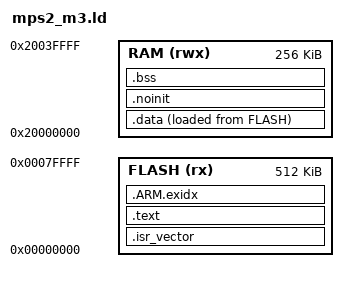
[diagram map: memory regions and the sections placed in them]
/* Linker script for QEMU "mps2-an385" (Cortex-M3): code at 0x00000000, RAM at 0x20000000. */
ENTRY(Reset_Handler)

MEMORY
{
    FLASH (rx)  : ORIGIN = 0x00000000, LENGTH = 512K
    RAM   (rwx) : ORIGIN = 0x20000000, LENGTH = 256K
}

_estack = ORIGIN(RAM) + LENGTH(RAM);

SECTIONS
{
    .isr_vector : { KEEP(*(.isr_vector)) } > FLASH
    .text : { *(.text*) *(.rodata*) . = ALIGN(4); } > FLASH
    .ARM.exidx : { *(.ARM.exidx*) } > FLASH
    _sidata = LOADADDR(.data);
    .data : { _sdata = .; *(.data*) . = ALIGN(4); _edata = .; } > RAM AT > FLASH
    .noinit (NOLOAD) : { *(.noinit*) } > RAM          /* survives a software reset only if the reset does not clear RAM */
    .bss (NOLOAD) : { _sbss = .; *(.bss*) *(COMMON) . = ALIGN(4); _ebss = .; } > RAM
    . = ALIGN(8);
    _end = .;
}
